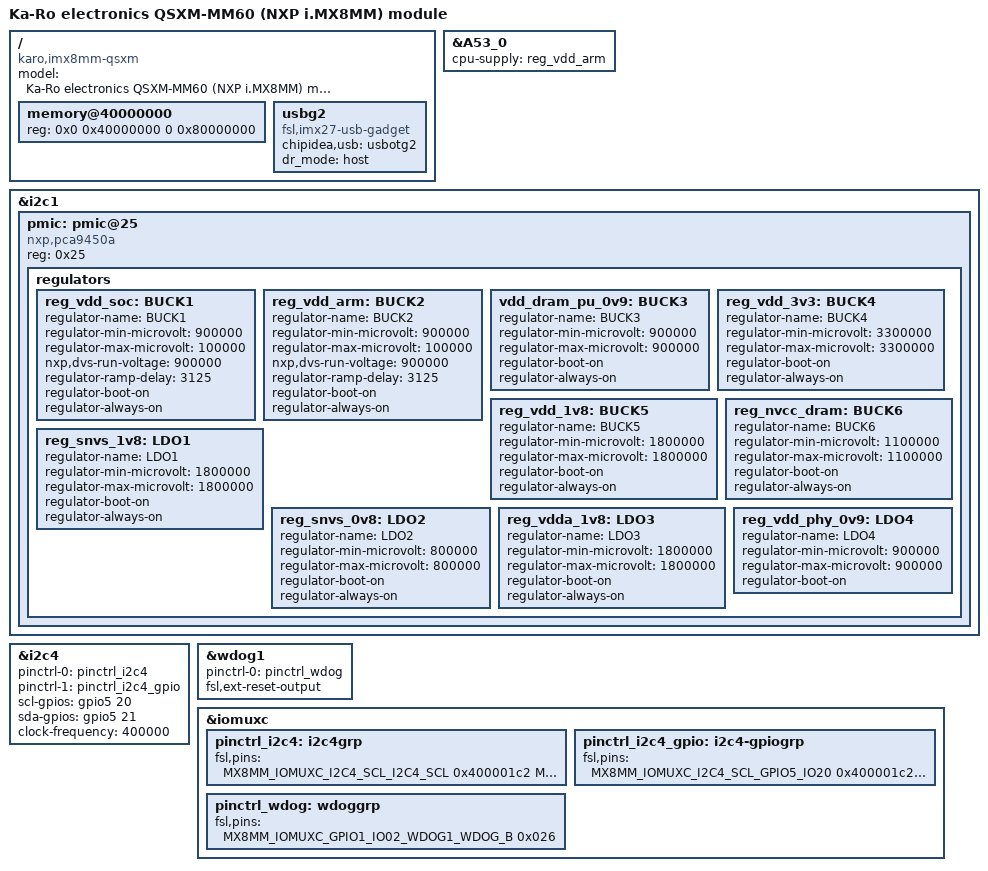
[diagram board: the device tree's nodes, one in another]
// SPDX-License-Identifier: (GPL-2.0 OR MIT)
/*
 * Copyright (C) 2020 Lothar Waßmann <LW@KARO-electronics.de>
 *
 */

/dts-v1/;

#include "imx8mm-karo.dtsi"

/ {
	model = "Ka-Ro electronics QSXM-MM60 (NXP i.MX8MM) module";
	compatible = "karo,imx8mm-qsxm", "fsl,imx8mm";

	memory@40000000 {
		device_type = "memory";
		reg = <0x0 0x40000000 0 0x80000000>;
	};

	/delete-node/ leds;

	usbg2: usbg2 {
		compatible = "fsl,imx27-usb-gadget";
		chipidea,usb = <&usbotg2>;
		dr_mode = "host";
		status = "okay";
	};
};

&A53_0 {
	cpu-supply = <&reg_vdd_arm>;
};

&i2c1 {
	pmic: pmic@25 {
		reg = <0x25>;
		compatible = "nxp,pca9450a";
		status = "okay";

		regulators {
			reg_vdd_soc: BUCK1 {
				regulator-name = "BUCK1";
				regulator-min-microvolt = <900000>;
				regulator-max-microvolt = <100000>;
				nxp,dvs-run-voltage = <900000>;
				regulator-ramp-delay = <3125>;
				regulator-boot-on;
				regulator-always-on;
			};

			reg_vdd_arm: BUCK2 {
				regulator-name = "BUCK2";
				regulator-min-microvolt = <900000>;
				regulator-max-microvolt = <100000>;
				nxp,dvs-run-voltage = <900000>;
				regulator-ramp-delay = <3125>;
				regulator-boot-on;
				regulator-always-on;
			};

			vdd_dram_pu_0v9: BUCK3 {
				regulator-name = "BUCK3";
				regulator-min-microvolt = <900000>;
				regulator-max-microvolt = <900000>;
				regulator-boot-on;
				regulator-always-on;
			};

			reg_vdd_3v3: BUCK4 {
				regulator-name = "BUCK4";
				regulator-min-microvolt = <3300000>;
				regulator-max-microvolt = <3300000>;
				regulator-boot-on;
				regulator-always-on;
			};

			reg_vdd_1v8: BUCK5 {
				regulator-name = "BUCK5";
				regulator-min-microvolt = <1800000>;
				regulator-max-microvolt = <1800000>;
				regulator-boot-on;
				regulator-always-on;
			};

			reg_nvcc_dram: BUCK6 {
				regulator-name = "BUCK6";
				regulator-min-microvolt = <1100000>;
				regulator-max-microvolt = <1100000>;
				regulator-boot-on;
				regulator-always-on;
			};

			reg_snvs_1v8: LDO1 {
				regulator-name = "LDO1";
				regulator-min-microvolt = <1800000>;
				regulator-max-microvolt = <1800000>;
				regulator-boot-on;
				regulator-always-on;
			};

			reg_snvs_0v8: LDO2 {
				regulator-name = "LDO2";
				regulator-min-microvolt = <800000>;
				regulator-max-microvolt = <800000>;
				regulator-boot-on;
				regulator-always-on;
			};

			reg_vdda_1v8: LDO3 {
				regulator-name = "LDO3";
				regulator-min-microvolt = <1800000>;
				regulator-max-microvolt = <1800000>;
				regulator-boot-on;
				regulator-always-on;
			};

			reg_vdd_phy_0v9: LDO4 {
				regulator-name = "LDO4";
				regulator-min-microvolt = <900000>;
				regulator-max-microvolt = <900000>;
				regulator-boot-on;
			};
		};
	};
};

&i2c4 {
	pinctrl-names = "default", "gpio";
	pinctrl-0 = <&pinctrl_i2c4>;
	pinctrl-1 = <&pinctrl_i2c4_gpio>;
	scl-gpios = <&gpio5 20 GPIO_ACTIVE_HIGH>;
	sda-gpios = <&gpio5 21 GPIO_ACTIVE_HIGH>;
	clock-frequency = <400000>;
	status = "okay";
};

&wdog1 {
	pinctrl-names = "default";
	pinctrl-0 = <&pinctrl_wdog>;
	fsl,ext-reset-output;
	status = "okay";
};

&iomuxc {
	pinctrl_i2c4: i2c4grp {
		fsl,pins = <
			MX8MM_IOMUXC_I2C4_SCL_I2C4_SCL			0x400001c2
			MX8MM_IOMUXC_I2C4_SDA_I2C4_SDA			0x400001c2
		>;
	};

	pinctrl_i2c4_gpio: i2c4-gpiogrp {
		fsl,pins = <
			MX8MM_IOMUXC_I2C4_SCL_GPIO5_IO20		0x400001c2
			MX8MM_IOMUXC_I2C4_SDA_GPIO5_IO21		0x400001c2
		>;
	};

	pinctrl_wdog: wdoggrp {
		fsl,pins = <
			MX8MM_IOMUXC_GPIO1_IO02_WDOG1_WDOG_B		0x026
		>;
	};
};
